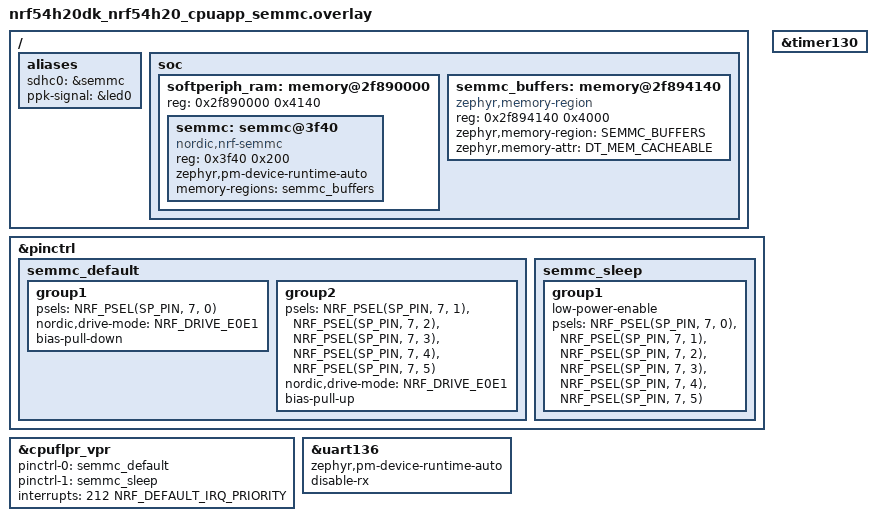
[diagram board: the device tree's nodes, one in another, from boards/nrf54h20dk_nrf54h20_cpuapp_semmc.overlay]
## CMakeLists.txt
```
#
# Copyright (c) 2026 Nordic Semiconductor ASA
#
# SPDX-License-Identifier: LicenseRef-Nordic-5-Clause
#

cmake_minimum_required(VERSION 3.20.0)

find_package(Zephyr REQUIRED HINTS $ENV{ZEPHYR_BASE})
project(sdmmc_performance)

target_sources(app PRIVATE src/main.c)
```

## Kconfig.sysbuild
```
#
# Copyright (c) 2026 Nordic Semiconductor ASA
#
# SPDX-License-Identifier: LicenseRef-Nordic-5-Clause
#

config SUPPORT_NETCORE_REMOTE_SLEEP_FOREVER
	bool
	default y if SOC_NRF54H20_CPUAPP

choice NETCORE
	default NETCORE_REMOTE_SLEEP_FOREVER if SUPPORT_NETCORE_REMOTE_SLEEP_FOREVER

config NETCORE_REMOTE_SLEEP_FOREVER
	bool "Remote sleep forever image"

endchoice

config NETCORE_IMAGE_NAME
	default "remote_sleep_forever" if NETCORE_REMOTE_SLEEP_FOREVER

config NETCORE_IMAGE_PATH
	default "${ZEPHYR_NRF_MODULE_DIR}/tests/benchmarks/power_consumption/common/remote_sleep_forever" if NETCORE_REMOTE_SLEEP_FOREVER

config NETCORE_REMOTE_BOARD_TARGET_CPUCLUSTER
	default "cpurad" if SOC_NRF54H20

source "share/sysbuild/Kconfig"
```

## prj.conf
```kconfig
CONFIG_CPU_LOAD=y
CONFIG_COUNTER=y

CONFIG_MAIN_STACK_SIZE=8192
CONFIG_UART_ASYNC_API=y

CONFIG_PM_DEVICE=y
CONFIG_PM_DEVICE_RUNTIME=y
CONFIG_POWEROFF=y
```

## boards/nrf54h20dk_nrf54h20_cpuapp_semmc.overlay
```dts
/*
 * Copyright (c) 2026 Nordic Semiconductor ASA
 *
 * SPDX-License-Identifier: LicenseRef-Nordic-5-Clause
 */

/ {
	aliases {
		sdhc0 = &semmc;
		ppk-signal = &led0;
		/delete-property/ led1;
	};
};

/delete-node/ &led1;

&pinctrl {
	semmc_default: semmc_default {
		group1 {
			psels = <NRF_PSEL(SP_PIN, 7, 0)>; /* CLK */
			nordic,drive-mode = <NRF_DRIVE_E0E1>;
			bias-pull-down;
		};

		group2 {
			psels = <NRF_PSEL(SP_PIN, 7, 1)>, /* D0 */
				<NRF_PSEL(SP_PIN, 7, 2)>, /* D1 */
				<NRF_PSEL(SP_PIN, 7, 3)>, /* D2 */
				<NRF_PSEL(SP_PIN, 7, 4)>, /* D3 */
				<NRF_PSEL(SP_PIN, 7, 5)>; /* CMMD */
			nordic,drive-mode = <NRF_DRIVE_E0E1>;
			bias-pull-up;
		};
	};

	semmc_sleep: semmc_sleep {
		group1 {
			low-power-enable;
			psels = <NRF_PSEL(SP_PIN, 7, 0)>,
				<NRF_PSEL(SP_PIN, 7, 1)>,
				<NRF_PSEL(SP_PIN, 7, 2)>,
				<NRF_PSEL(SP_PIN, 7, 3)>,
				<NRF_PSEL(SP_PIN, 7, 4)>,
				<NRF_PSEL(SP_PIN, 7, 5)>;
		};
	};
};

&cpuflpr_vpr {
	pinctrl-0 = <&semmc_default>;
	pinctrl-1 = <&semmc_sleep>;
	pinctrl-names = "default", "sleep";
	interrupts = <212 NRF_DEFAULT_IRQ_PRIORITY>;
	status = "okay";
	/delete-property/ execution-memory;
};

/delete-node/ &cpuflpr_code_data;
/delete-node/ &cpuapp_cpuflpr_ipc_shm;
/delete-node/ &cpuflpr_cpuapp_ipc_shm;
/delete-node/ &cpuapp_cpuflpr_ipc;

/ {
	soc {
		softperiph_ram: memory@2f890000 {
			reg = <0x2f890000 0x4140>;
			ranges = <0 0x2f890000 0x4140>;
			#address-cells = <1>;
			#size-cells = <1>;

			semmc: semmc@3f40 {
				compatible = "nordic,nrf-semmc";
				#address-cells = <1>;
				#size-cells = <0>;
				reg = <0x3f40 0x200>;
				zephyr,pm-device-runtime-auto;
				memory-regions = <&semmc_buffers>;
			};
		};

		semmc_buffers: memory@2f894140 {
			compatible = "zephyr,memory-region", "mmio-sram";
			reg = <0x2f894140 0x4000>;
			#memory-region-cells = <0>;
			zephyr,memory-region = "SEMMC_BUFFERS";
			zephyr,memory-attr = <DT_MEM_CACHEABLE>;
		};
	};
};

tst_timer: &timer130 {
	status = "okay";
};

&uart136 {
	zephyr,pm-device-runtime-auto;
	disable-rx;
};
```

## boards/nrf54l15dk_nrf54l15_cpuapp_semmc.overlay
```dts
/*
 * Copyright (c) 2026 Nordic Semiconductor ASA
 *
 * SPDX-License-Identifier: LicenseRef-Nordic-5-Clause
 */

/ {
	aliases {
		sdhc0 = &semmc;
		ppk-signal = &button3;
	};
};

&pinctrl {
	semmc_default: semmc_default {
		group1 {
			psels = <NRF_PSEL(SP_PIN, 2, 1)>; /* CLK */
			nordic,drive-mode = <NRF_DRIVE_E0E1>;
			bias-pull-down;
		};

		group2 {
			psels = <NRF_PSEL(SP_PIN, 2, 2)>, /* D0 */
				<NRF_PSEL(SP_PIN, 2, 4)>, /* D1 */
				<NRF_PSEL(SP_PIN, 2, 3)>, /* D2 */
				<NRF_PSEL(SP_PIN, 2, 0)>, /* D3 */
				<NRF_PSEL(SP_PIN, 2, 5)>; /* CMMD */
			nordic,drive-mode = <NRF_DRIVE_E0E1>;
			bias-pull-up;
		};
	};

	semmc_sleep: semmc_sleep {
		group1 {
			low-power-enable;
			psels = <NRF_PSEL(SP_PIN, 2, 1)>,
				<NRF_PSEL(SP_PIN, 2, 2)>,
				<NRF_PSEL(SP_PIN, 2, 4)>,
				<NRF_PSEL(SP_PIN, 2, 3)>,
				<NRF_PSEL(SP_PIN, 2, 0)>,
				<NRF_PSEL(SP_PIN, 2, 5)>;
		};
	};
};

&cpuflpr_vpr {
	pinctrl-0 = <&semmc_default>;
	pinctrl-1 = <&semmc_sleep>;
	pinctrl-names = "default", "sleep";
	interrupts = <76 NRF_DEFAULT_IRQ_PRIORITY>;
	status = "okay";
};

/ {
	soc {
		softperiph_ram: memory@2003b400 {
			reg = <0x2003b400 0x4c00>;
			ranges = <0 0x2003b400 0x4c00>;
			#address-cells = <1>;
			#size-cells = <1>;

			semmc: semmc@4200 {
				compatible = "nordic,nrf-semmc";
				#address-cells = <1>;
				#size-cells = <0>;
				reg = <0x4200 0x200>;
				zephyr,pm-device-runtime-auto;
			};
		};
	};
};

tst_timer: &timer22 {
	status = "okay";
};

&uart20 {
	zephyr,pm-device-runtime-auto;
	disable-rx;
};

&gpio2 {
	hs-bias = <2>;
};
```

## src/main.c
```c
/*
 * Copyright (c) 2026 Nordic Semiconductor ASA
 *
 * SPDX-License-Identifier: LicenseRef-Nordic-5-Clause
 */

#include <zephyr/kernel.h>
#include <zephyr/device.h>
#if defined(CONFIG_MMC_STACK)
#include <zephyr/sd/mmc.h>
#else
#include <zephyr/sd/sdmmc.h>
#endif
#include <zephyr/drivers/disk.h>
#include <zephyr/drivers/counter.h>
#include <zephyr/sys/cpu_load.h>
#include <zephyr/drivers/gpio.h>

#define MAX_CPU_LOAD_VALUES_HELD	   32
#define TEST_TIMER_COUNT_TIME_LIMIT_MS	   10000
#define DEAD_TIME_MS			   1000
#define CPU_LOAD_MONITOR_THREAD_STACK_SIZE 4096
#define CPU_LOAD_MONITOR_PERIOD_MS	   25

#define MAX_BLOCK_COUNT	     64
#define BLOCK_SIZE	     512
#define MAX_TEST_BUFFER_SIZE (BLOCK_SIZE * MAX_BLOCK_COUNT)
#define SDMMC_UNALIGN_OFFSET 1
#define START_OFFSET	     0U

#define MAX_BUSY_RETRIERS 2

static const struct device *const sdmmc_dev = DEVICE_DT_GET(DT_ALIAS(sdhc0));
const struct device *const tst_timer_dev = DEVICE_DT_GET(DT_NODELABEL(tst_timer));
static const struct gpio_dt_spec ppk_signal = GPIO_DT_SPEC_GET(DT_ALIAS(ppk_signal), gpios);

static struct sd_card card;
static uint8_t test_buffer[MAX_TEST_BUFFER_SIZE] __aligned(CONFIG_SDHC_BUFFER_ALIGNMENT);
static uint32_t block_size;
static uint32_t block_count;

static K_SEM_DEFINE(cpu_load_start_sem, 0, 1);
static K_SEM_DEFINE(cpu_load_stop_sem, 0, 1);
static K_SEM_DEFINE(cpu_load_calc_done_sem, 0, 1);
static K_SEM_DEFINE(cpu_load_thread_terminate_sem, 0, 1);

typedef int (*sdmmc_operation_fn)(struct sd_card *card, uint8_t *buf, uint32_t start_block,
				  uint32_t num_blocks);

static int sdmmc_read_operation(struct sd_card *card, uint8_t *buf, uint32_t start_block,
				uint32_t num_blocks)
{
#if defined(CONFIG_MMC_STACK)
	return mmc_read_blocks(card, buf, start_block, num_blocks);
#else
	return sdmmc_read_blocks(card, buf, start_block, num_blocks);
#endif
}

static int sdmmc_write_operation(struct sd_card *card, uint8_t *buf, uint32_t start_block,
				 uint32_t num_blocks)
{
#if defined(CONFIG_MMC_STACK)
	return mmc_write_blocks(card, (const uint8_t *)buf, start_block, num_blocks);
#else
	return sdmmc_write_blocks(card, (const uint8_t *)buf, start_block, num_blocks);
#endif
}

#if !defined(CONFIG_MMC_STACK)
static int sdmmc_erase_operation(struct sd_card *card, uint8_t *buf, uint32_t start_block,
				 uint32_t num_blocks)
{
	ARG_UNUSED(buf);

	return sdmmc_erase_blocks(card, start_block, num_blocks);
}
#endif

/*
 * Test timer setup
 * for flash operations duration measurement
 */
static void configure_test_timer(const struct device *timer_dev, uint32_t count_time_ms)
{
	struct counter_alarm_cfg counter_cfg;

	counter_cfg.flags = 0;
	counter_cfg.ticks = counter_us_to_ticks(timer_dev, (uint64_t)count_time_ms * 1000);
	counter_cfg.user_data = &counter_cfg;
}

static int test_setup(void)
{
	int ret;

	ret = gpio_is_ready_dt(&ppk_signal);
	if (ret != 1) {
		printk("PPK signaling GPIO is not ready\n");
		return -1;
	}

	ret = gpio_pin_configure_dt(&ppk_signal, GPIO_OUTPUT_ACTIVE);
	if (ret != 0) {
		printk("Failed to configure PPK signaling GPIO\n");
		return -2;
	}

	configure_test_timer(tst_timer_dev, TEST_TIMER_COUNT_TIME_LIMIT_MS);

	if (device_is_ready(sdmmc_dev) != 1) {
		printk("SDCARD/eMMC device not ready\n");
		return -3;
	}

#if !defined(CONFIG_MMC_STACK)
	/* This step depends on the device (SDCARD/eMMC) */
	if (sd_is_card_present(sdmmc_dev) != 1) {
		printk("SDCARD not present in slot\n");
		return -4;
	};
#endif

	ret = sd_init(sdmmc_dev, &card);
	if (ret != 0) {
		printk("SDCARD/eMMC init failed: %d\n", ret);
		return -5;
	}

#if defined(CONFIG_MMC_STACK)
	ret = mmc_ioctl(&card, DISK_IOCTL_GET_SECTOR_COUNT, &block_count);
#else
	ret = sdmmc_ioctl(&card, DISK_IOCTL_GET_SECTOR_COUNT, &block_count);
#endif
	if (ret != 0) {
		printk("IOCTL block count read failed: %d\n", ret);
		return -6;
	}
	printk("SDCARD/eMMC block count: %u\n", block_count);

#if defined(CONFIG_MMC_STACK)
	ret = mmc_ioctl(&card, DISK_IOCTL_GET_SECTOR_SIZE, &block_size);
#else
	ret = sdmmc_ioctl(&card, DISK_IOCTL_GET_SECTOR_SIZE, &block_size);
#endif
	if (ret != 0) {
		printk("IOCTL block size read failed: %d\n", ret);
		return -7;
	}
	printk("SDCARD/eMMC block size: %u\n", block_size);

	k_msleep(DEAD_TIME_MS);
	return 0;
}

static void test_sdmmc_operation(uint32_t operation_size_in_blocks, sdmmc_operation_fn operation,
				 const char *operation_name)
{
	int ret;
	uint32_t tst_timer_value = 0;
	uint64_t timer_value_us = 0;
	uint32_t required_operation_repeats = 1;
	uint32_t operation_block_count = operation_size_in_blocks;
	int32_t cpu_load;

	if (operation_size_in_blocks > MAX_BLOCK_COUNT) {
		/* Cannot be done in one shot due to CPU RAM limitation */
		required_operation_repeats = operation_size_in_blocks / MAX_BLOCK_COUNT;
		operation_block_count = MAX_BLOCK_COUNT;
	}

	printk("SDCARD/eMMC %s test [size: %u blocks]\n", operation_name, operation_size_in_blocks);
	printk("Operation repeats: %u\n", required_operation_repeats);
	printk("Single operation block count: %u\n", operation_block_count);
	memset(test_buffer, 0xAB, MAX_TEST_BUFFER_SIZE);

	cpu_load_get(true);
	gpio_pin_set_dt(&ppk_signal, 1);
	counter_reset(tst_timer_dev);
	counter_start(tst_timer_dev);
	for (uint32_t i = 0; i < required_operation_repeats; i++) {
		ret = operation(&card, test_buffer, START_OFFSET, operation_block_count);
	}
	counter_get_value(tst_timer_dev, &tst_timer_value);
	counter_stop(tst_timer_dev);
	gpio_pin_set_dt(&ppk_signal, 0);
	cpu_load = cpu_load_get(true);

	if (ret != 0) {
		printk("!!!! SDCARD/eMMC %s error: %d !!!!\n", operation_name, ret);
	}

	timer_value_us = counter_ticks_to_us(tst_timer_dev, tst_timer_value);

	printk("### Summary ###\n");
	printk("SDCARD/eMMC %s [size: %u blocks] took: %llu us\n", operation_name,
	       operation_size_in_blocks, timer_value_us);

	if ((ret == 0) && (timer_value_us > 0)) {
		uint64_t rate =
			(uint64_t)operation_size_in_blocks * BLOCK_SIZE * 1000ULL / timer_value_us;

		printk("SDCARD/eMMC %s rate: %llu.%03llu MB/s\n", operation_name, rate / 1000,
		       rate % 1000);
	}

	if (cpu_load > 0) {
		printk("CPU load %d,%d%%\n", cpu_load / 10, cpu_load % 10);
	} else {
		printk("CPU load get failed: %d\n", cpu_load);
	}

	k_msleep(DEAD_TIME_MS);
}

int main(void)
{
	int ret;
	uint32_t test_operation_size[] = {1, 4, 128, 512, 2048, 16384};

	printk("SDCARD/eMMC performance benchmark %s\n", CONFIG_BOARD_TARGET);

	ret = test_setup();
	if (ret) {
		printk("Test setup failed: %d\n", ret);
		return -1;
	}

	for (int i = 0; i < ARRAY_SIZE(test_operation_size); i++) {
		printk("*********************************************\n");
		printk("**** [Step %u] SDCARD/eMMC operation size: %u blocks ****\n", i + 1,
		       test_operation_size[i]);
#if !defined(CONFIG_MMC_STACK)
		test_sdmmc_operation(test_operation_size[i], sdmmc_erase_operation, "erase");
#endif
		test_sdmmc_operation(test_operation_size[i], sdmmc_write_operation, "write");
		test_sdmmc_operation(test_operation_size[i], sdmmc_read_operation, "read");
	}

	printk("Done\n");

	return 0;
}
```
